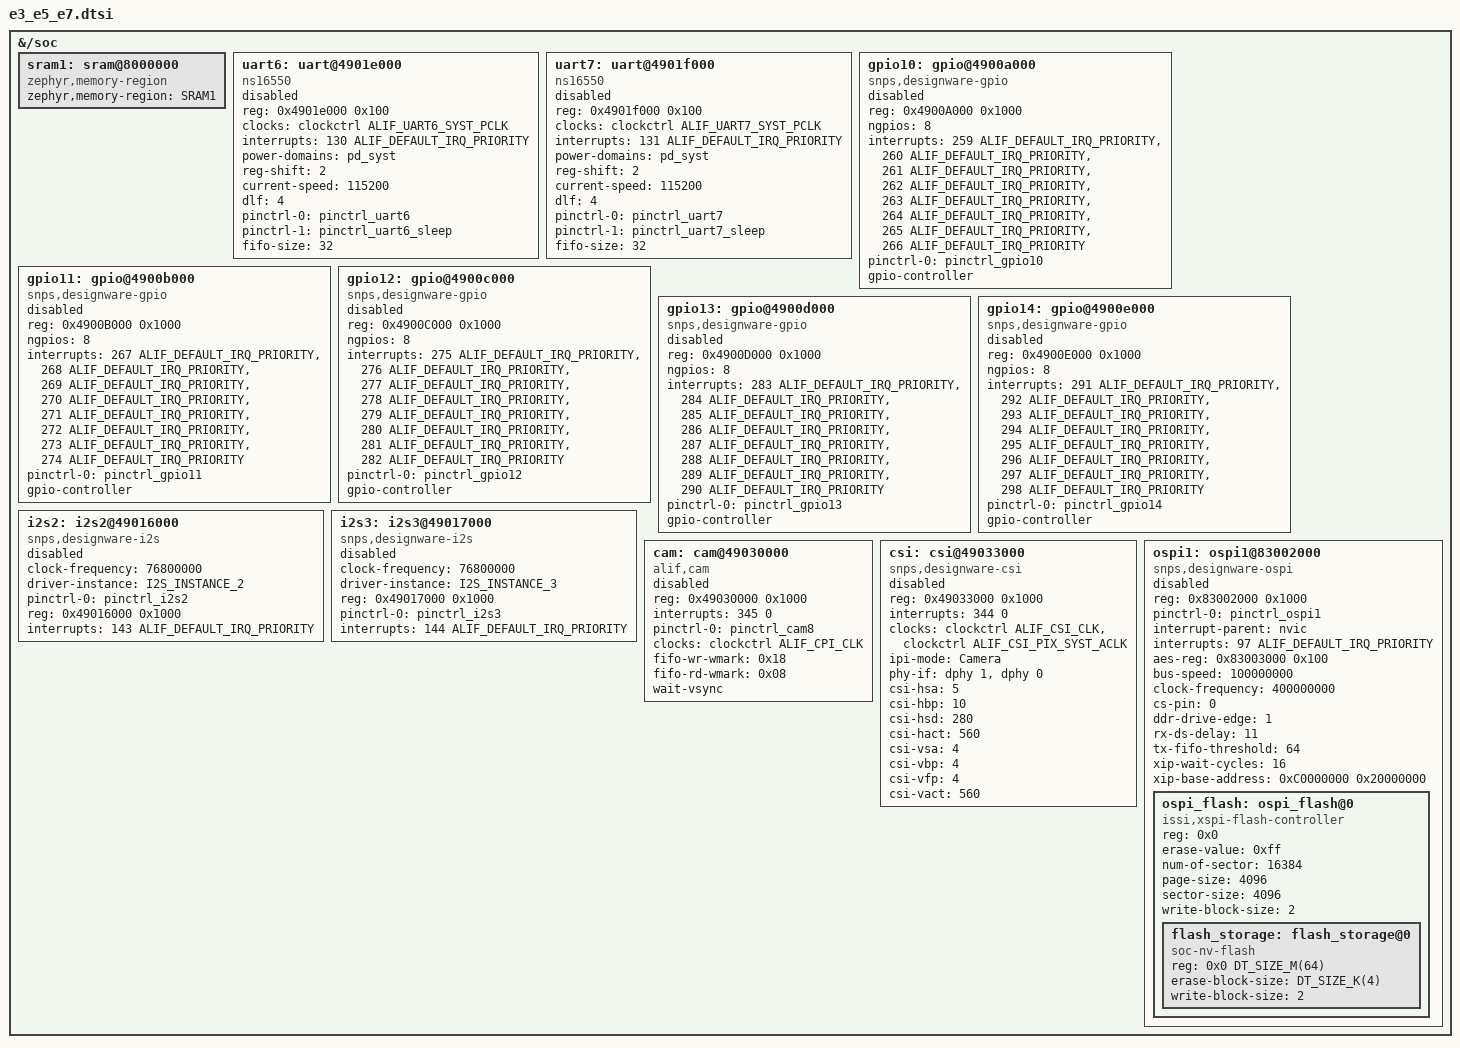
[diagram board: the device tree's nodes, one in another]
/* Copyright (c) 2025 Alif Semiconductor
 *
 * SPDX-License-Identifier: Apache-2.0
 */

#include <zephyr/dt-bindings/clock/alif_ensemble_clocks.h>
#include "e1.dtsi"

&{/soc} {
	sram1: sram@8000000 {
		compatible = "zephyr,memory-region","mmio-sram";
		zephyr,memory-region = "SRAM1";
	};

	uart6: uart@4901e000 {
		compatible = "ns16550";
		reg = <0x4901e000 0x100>;
		clocks = <&clockctrl ALIF_UART6_SYST_PCLK>;
		interrupts = <130 ALIF_DEFAULT_IRQ_PRIORITY>;
		power-domains = <&pd_syst>;
		reg-shift = <2>;
		current-speed = <115200>;
		dlf = <4>;
		pinctrl-0 = <&pinctrl_uart6>;
		pinctrl-1 = <&pinctrl_uart6_sleep>;
		pinctrl-names = "default", "sleep";
		fifo-size = <32>;
		status = "disabled";
	};
	uart7: uart@4901f000 {
		compatible = "ns16550";
		reg = <0x4901f000 0x100>;
		clocks = <&clockctrl ALIF_UART7_SYST_PCLK>;
		interrupts = <131 ALIF_DEFAULT_IRQ_PRIORITY>;
		power-domains = <&pd_syst>;
		reg-shift = <2>;
		current-speed = <115200>;
		dlf = <4>;
		pinctrl-0 = <&pinctrl_uart7>;
		pinctrl-1 = <&pinctrl_uart7_sleep>;
		pinctrl-names = "default", "sleep";
		fifo-size = <32>;
		status = "disabled";
	};

	gpio10: gpio@4900a000 {
		compatible = "snps,designware-gpio";
		reg = <0x4900A000 0x1000>;
		ngpios = <8>;
		interrupts = <259 ALIF_DEFAULT_IRQ_PRIORITY>,
			     <260 ALIF_DEFAULT_IRQ_PRIORITY>,
			     <261 ALIF_DEFAULT_IRQ_PRIORITY>,
			     <262 ALIF_DEFAULT_IRQ_PRIORITY>,
			     <263 ALIF_DEFAULT_IRQ_PRIORITY>,
			     <264 ALIF_DEFAULT_IRQ_PRIORITY>,
			     <265 ALIF_DEFAULT_IRQ_PRIORITY>,
			     <266 ALIF_DEFAULT_IRQ_PRIORITY>;
		pinctrl-0 = < &pinctrl_gpio10 >;
		pinctrl-names = "default";
		gpio-controller;
		#gpio-cells = <2>;
		status = "disabled";
	};

	gpio11: gpio@4900b000 {
		compatible = "snps,designware-gpio";
		reg = <0x4900B000 0x1000>;
		ngpios = <8>;
		interrupts = <267 ALIF_DEFAULT_IRQ_PRIORITY>,
			     <268 ALIF_DEFAULT_IRQ_PRIORITY>,
			     <269 ALIF_DEFAULT_IRQ_PRIORITY>,
			     <270 ALIF_DEFAULT_IRQ_PRIORITY>,
			     <271 ALIF_DEFAULT_IRQ_PRIORITY>,
			     <272 ALIF_DEFAULT_IRQ_PRIORITY>,
			     <273 ALIF_DEFAULT_IRQ_PRIORITY>,
			     <274 ALIF_DEFAULT_IRQ_PRIORITY>;
		pinctrl-0 = < &pinctrl_gpio11 >;
		pinctrl-names = "default";
		gpio-controller;
		#gpio-cells = <2>;
		status = "disabled";
	};

	gpio12: gpio@4900c000 {
		compatible = "snps,designware-gpio";
		reg = <0x4900C000 0x1000>;
		ngpios = <8>;
		interrupts = <275 ALIF_DEFAULT_IRQ_PRIORITY>,
			     <276 ALIF_DEFAULT_IRQ_PRIORITY>,
			     <277 ALIF_DEFAULT_IRQ_PRIORITY>,
			     <278 ALIF_DEFAULT_IRQ_PRIORITY>,
			     <279 ALIF_DEFAULT_IRQ_PRIORITY>,
			     <280 ALIF_DEFAULT_IRQ_PRIORITY>,
			     <281 ALIF_DEFAULT_IRQ_PRIORITY>,
			     <282 ALIF_DEFAULT_IRQ_PRIORITY>;
		pinctrl-0 = < &pinctrl_gpio12 >;
		pinctrl-names = "default";
		gpio-controller;
		#gpio-cells = <2>;
		status = "disabled";
	};

	gpio13: gpio@4900d000 {
		compatible = "snps,designware-gpio";
		reg = <0x4900D000 0x1000>;
		ngpios = <8>;
		interrupts = <283 ALIF_DEFAULT_IRQ_PRIORITY>,
			     <284 ALIF_DEFAULT_IRQ_PRIORITY>,
			     <285 ALIF_DEFAULT_IRQ_PRIORITY>,
			     <286 ALIF_DEFAULT_IRQ_PRIORITY>,
			     <287 ALIF_DEFAULT_IRQ_PRIORITY>,
			     <288 ALIF_DEFAULT_IRQ_PRIORITY>,
			     <289 ALIF_DEFAULT_IRQ_PRIORITY>,
			     <290 ALIF_DEFAULT_IRQ_PRIORITY>;
		pinctrl-0 = < &pinctrl_gpio13 >;
		pinctrl-names = "default";
		gpio-controller;
		#gpio-cells = <2>;
		status = "disabled";
	};

	gpio14: gpio@4900e000 {
		compatible = "snps,designware-gpio";
		reg = <0x4900E000 0x1000>;
		ngpios = <8>;
		interrupts = <291 ALIF_DEFAULT_IRQ_PRIORITY>,
			     <292 ALIF_DEFAULT_IRQ_PRIORITY>,
			     <293 ALIF_DEFAULT_IRQ_PRIORITY>,
			     <294 ALIF_DEFAULT_IRQ_PRIORITY>,
			     <295 ALIF_DEFAULT_IRQ_PRIORITY>,
			     <296 ALIF_DEFAULT_IRQ_PRIORITY>,
			     <297 ALIF_DEFAULT_IRQ_PRIORITY>,
			     <298 ALIF_DEFAULT_IRQ_PRIORITY>;
		pinctrl-0 = < &pinctrl_gpio14 >;
		pinctrl-names = "default";
		gpio-controller;
		#gpio-cells = <2>;
		status = "disabled";
	};

	i2s2: i2s2@49016000 {
		compatible = "snps,designware-i2s";
		clock-frequency = <76800000>;
		driver-instance	= "I2S_INSTANCE_2";
		pinctrl-names = "default";
		pinctrl-0 = <&pinctrl_i2s2>;
		reg = <0x49016000 0x1000>;
		interrupts = <143 ALIF_DEFAULT_IRQ_PRIORITY>;
		status = "disabled";
	};

	i2s3: i2s3@49017000 {
		compatible = "snps,designware-i2s";
		clock-frequency = <76800000>;
		driver-instance	= "I2S_INSTANCE_3";
		reg = <0x49017000 0x1000>;
		pinctrl-names = "default";
		pinctrl-0 = <&pinctrl_i2s3>;
		interrupts = <144 ALIF_DEFAULT_IRQ_PRIORITY>;
		status = "disabled";
	};

	cam: cam@49030000 {
		compatible = "alif,cam";
		reg = <0x49030000 0x1000>;
		interrupts = <345 0>;
		pinctrl-0 = <&pinctrl_cam8>;
		pinctrl-names = "default";
		clocks = <&clockctrl ALIF_CPI_CLK>;
		clock-names = "cam_clk";
		fifo-wr-wmark = <0x18>;
		fifo-rd-wmark = <0x08>;
		wait-vsync;
		status = "disabled";
	};

	csi: csi@49033000 {
		compatible = "snps,designware-csi";
		reg = <0x49033000 0x1000>;
		interrupts = <344 0>;

		clocks = <&clockctrl ALIF_CSI_CLK>, <&clockctrl ALIF_CSI_PIX_SYST_ACLK>;
		clock-names = "csi_clk", "pix_clk";
		ipi-mode = "Camera";
		phy-if = <&dphy 1>, <&dphy 0>;

		csi-hsa = <5>;
		csi-hbp = <10>;
		csi-hsd = <280>;
		csi-hact = <560>;
		csi-vsa = <4>;
		csi-vbp = <4>;
		csi-vfp = <4>;
		csi-vact = <560>;
		status = "disabled";
	};

	ospi1: ospi1@83002000 {
		compatible = "snps,designware-ospi";
		#address-cells = <1>;
		#size-cells = <0>;
		reg = <0x83002000 0x1000>;
		pinctrl-0 = <&pinctrl_ospi1>;
		pinctrl-names = "default";
		interrupt-parent = <&nvic>;
		interrupts = <97 ALIF_DEFAULT_IRQ_PRIORITY>;
		aes-reg = <0x83003000 0x100>;
		bus-speed = <100000000>;
		clock-frequency = <400000000>;
		cs-pin = <0>;
		ddr-drive-edge = <1>;
		rx-ds-delay = <11>;
		tx-fifo-threshold = <64>;
		xip-wait-cycles = <16>;
		xip-base-address = <0xC0000000 0x20000000>;
		status = "disabled";

		ospi_flash: ospi_flash@0 {
			compatible = "issi,xspi-flash-controller";
			reg = <0x0>;
			erase-value = <0xff>;
			num-of-sector = <16384>;
			page-size = <4096>;
			sector-size = <4096>;
			write-block-size = <2>;

			/* Flash Size 64MB */
			#address-cells = <1>;
			#size-cells = <1>;

			flash_storage: flash_storage@0 {
				compatible = "soc-nv-flash";
				reg = <0x0 DT_SIZE_M(64)>;
				erase-block-size = <DT_SIZE_K(4)>;
				write-block-size = <2>;
			};
		};
	};
};
